# S32K322_M7 register map
Vendor: NXP Semiconductors; File version: 1.0
CPU: CM7 r0p1, little endian, MPU, FPU, VTOR, 4 interrupt priority bits
Registers are 32-bit, read-write, reset 0x0 unless marked. A register's access mark holds for its fields unless they carry their own. Offsets are from the block's base; [hi:lo] are bit positions; {n}, {i} and the like mark numbered series; 'fields as' and 'values as' point back to an identical list.

## ERM
Base 0x4025C000
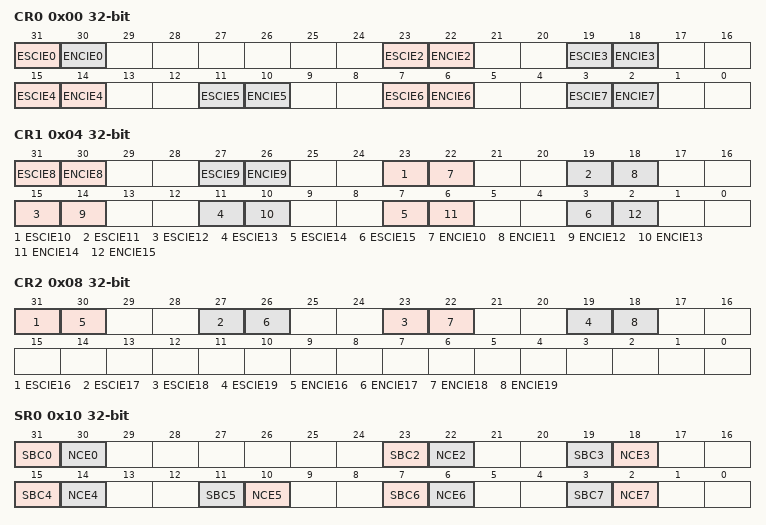
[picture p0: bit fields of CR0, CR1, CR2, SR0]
0x00 CR0 — ERM Configuration Register 0
  [31] ESCIE0
    0=DISABLE (Interrupt notification of Memory 0 single-bit correction events is disabled.); 1=ENABLE (Interrupt notification of Memory 0 single-bit correction events is enabled.)
  [30] ENCIE0
    0=DISABLE (Interrupt notification of Memory 0 non-correctable error events is disabled.); 1=ENABLE (Interrupt notification of Memory 0 non-correctable error events is enabled.)
  [31-4n] ESCIE{n} (n=2..7)
    0=DISABLE (Interrupt notification of Memory {n} single-bit correction events is disabled.); 1=ENABLE (Interrupt notification of Memory {n} single-bit correction events is enabled.)
  [30-4n] ENCIE{n} (n=2..7)
    0=DISABLE (Interrupt notification of Memory {n} non-correctable error events is disabled.); 1=ENABLE (Interrupt notification of Memory {n} non-correctable error events is enabled.)
0x04 CR1 — ERM Configuration Register 1
  [63-4n] ESCIE{n} (n=8..15)
    values as CR0.ESCIE2
  [62-4n] ENCIE{n} (n=8..15)
    values as CR0.ENCIE2
0x08 CR2 — ERM Configuration Register 2
  [95-4n] ESCIE{n} (n=16..19)
    values as CR0.ESCIE2
  [94-4n] ENCIE{n} (n=16..19)
    values as CR0.ENCIE2
0x10 SR0 write-1-clears — ERM Status Register 0
  [31] SBC0 write-1-clears
    0=NO_EVENT (No single-bit correction event on Memory 0 detected.); 1=EVENT (Single-bit correction event on Memory 0 detected.)
  [30] NCE0 write-1-clears
    0=NO_ERROR (No non-correctable error event on Memory 0 detected.); 1=ERROR (Non-correctable error event on Memory 0 detected.)
  [23] SBC2 write-1-clears
    0=NO_EVENT (No single-bit correction event on Memory 2 detected.); 1=EVENT (Single-bit correction event on Memory 2 detected.)
  [30-4n] NCE{n} write-1-clears (n=2..7)
    0=NO_ERROR (No non-correctable error event on Memory {n} detected.); 1=ERROR (Non-correctable error event on Memory {n} detected.)
  [19] SBC3 write-1-clears
    0=NO_EVENT (No single-bit correction event on Memory 3 detected.); 1=EVENT (Single-bit correction event on Memory 3 detected.)
  [15] SBC4 write-1-clears
    0=NO_EVENT (No single-bit correction event on Memory 4 detected.); 1=EVENT (Single-bit correction event on Memory 4 detected.)
  [11] SBC5 write-1-clears
    0=NO_EVENT (No single-bit correction event on Memory 5 detected.); 1=CORR_EVENT (Single-bit correction event on Memory 5 detected.)
  [7] SBC6 write-1-clears
    0=NO_EVENT (No single-bit correction event on Memory 6 detected.); 1=EVENT (Single-bit correction event on Memory 6 detected.)
  [3] SBC7 write-1-clears
    0=NO_EVENT (No single-bit correction event on Memory 7 detected.); 1=EVENT (Single-bit correction event on Memory 7 detected.)
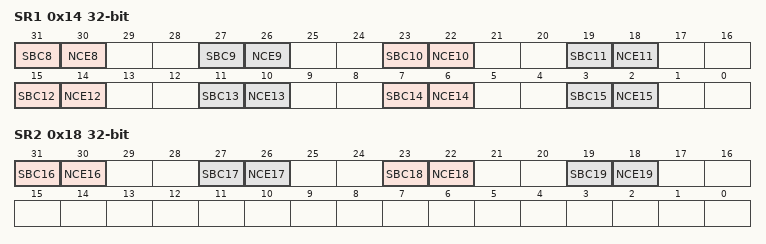
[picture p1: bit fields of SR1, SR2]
0x14 SR1 write-1-clears — ERM Status Register 1
  [63-4n] SBC{n} write-1-clears (n=8..15)
    0=NO_EVENT (No single-bit correction event on Memory {n} detected.); 1=EVENT (Single-bit correction event on Memory {n} detected.)
  [62-4n] NCE{n} write-1-clears (n=8..15)
    values as SR0.NCE2
0x18 SR2 write-1-clears — ERM Status Register 2
  [95-4n] SBC{n} write-1-clears (n=16..19)
    values as SR1.SBC8
  [94-4n] NCE{n} write-1-clears (n=16..19)
    values as SR0.NCE2
0x100 EAR0 ro — ERM Memory 0 Error Address Register
  [31:0] EAR
0x104 SYN0 ro — ERM Memory 0 Syndrome Register
  [31:24] SYNDROME
0x108 CORR_ERR_CNT0 — ERM Memory 0 Correctable Error Count Register
  [7:0] COUNT — Memory n Correctable Error Count
{0x108+0x10*i} CORR_ERR_CNT{i} (i=2..19) — ERM Memory {i} Correctable Error Count Register
  [7:0] COUNT — Memory n Correctable Error Count
{0x100+0x10*i} EAR{i} ro (i=10..19) — ERM Memory {i} Error Address Register
  [31:0] EAR
{0x104+0x10*i} SYN{i} ro (i=10..16) — ERM Memory {i} Syndrome Register
  [31:24] SYNDROME
